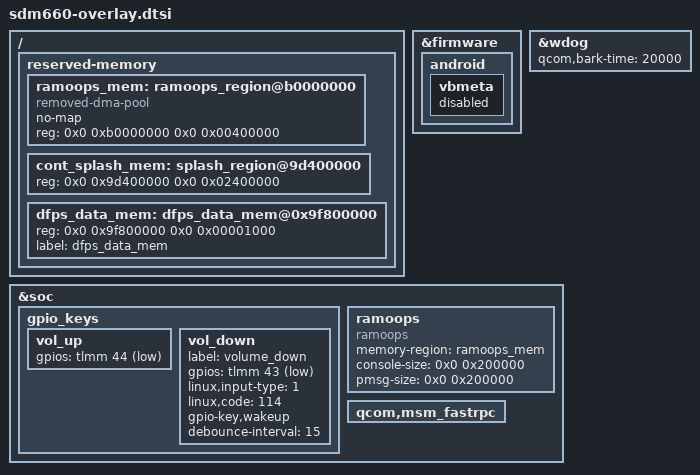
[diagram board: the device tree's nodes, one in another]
/* Copyright (c) 2016-2019, The Linux Foundation. All rights reserved.
 *
 * This program is free software; you can redistribute it and/or modify
 * it under the terms of the GNU General Public License version 2 and
 * only version 2 as published by the Free Software Foundation.
 *
 * This program is distributed in the hope that it will be useful,
 * but WITHOUT ANY WARRANTY; without even the implied warranty of
 * MERCHANTABILITY or FITNESS FOR A PARTICULAR PURPOSE.  See the
 * GNU General Public License for more details.
 */

/ {
	reserved-memory {
		ramoops_mem: ramoops_region@b0000000 {
			compatible = "removed-dma-pool";
			no-map;
			reg = <0x0 0xb0000000 0x0 0x00400000>;
		};

		cont_splash_mem: splash_region@9d400000 {
			reg = <0x0 0x9d400000 0x0 0x02400000>;
		};

		/delete-node/ dfps_data_mem@0x9f7ff000;

		dfps_data_mem: dfps_data_mem@0x9f800000 {
			reg = <0x0 0x9f800000 0x0 0x00001000>;
			label = "dfps_data_mem";
		};
	};
};

&firmware {
	android {
		vbmeta {
			status = "disabled";
		};
	};
};

&wdog {
	qcom,bark-time = <20000>;
};

&soc {
	gpio_keys {
		/delete-node/ camera_focus;
		/delete-node/ camera_snapshot;

		vol_up {
			gpios = <&tlmm 44 0x1>;
		};

		vol_down {
			label = "volume_down";
			gpios = <&tlmm 43 0x1>;
			linux,input-type = <1>;
			linux,code = <114>;
			gpio-key,wakeup;
			debounce-interval = <15>;
		};
	};

	ramoops {
		compatible = "ramoops";
		status = "ok";
		memory-region = <&ramoops_mem>;

		console-size = <0x0 0x200000>; /* 2 MB */
		pmsg-size    = <0x0 0x200000>; /* 2 MB */
	};

	qcom,msm_fastrpc {
		/delete-property/ qcom,fastrpc-adsp-sensors-pdr;
	};
};
